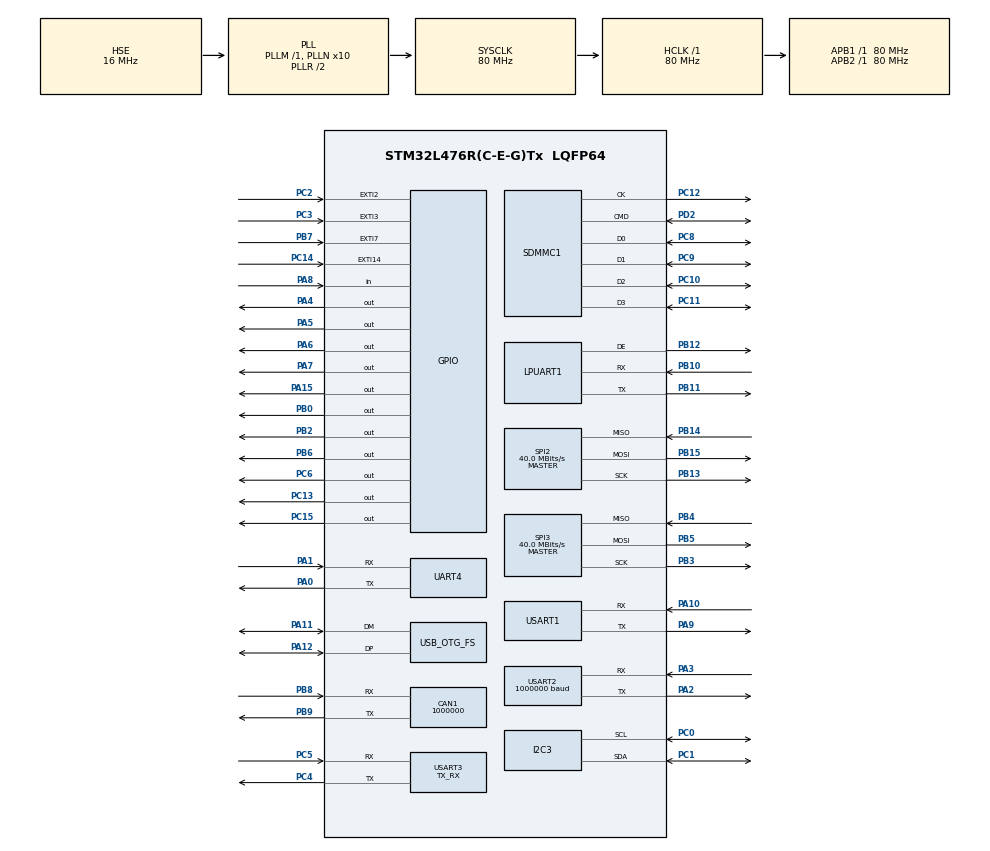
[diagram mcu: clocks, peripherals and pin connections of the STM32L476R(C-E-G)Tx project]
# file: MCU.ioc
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AL94.I-CUBE-USBD-COMPOSITE.1.0.3._STM32F1_DEVICE=false
AL94.I-CUBE-USBD-COMPOSITE.1.0.3._USBD_CDC_ACM_COUNT=1
AL94.I-CUBE-USBD-COMPOSITE.1.0.3._USBD_USE_CDC_ACM=true
AL94.I-CUBE-USBD-COMPOSITE.1.0.3._USBD_USE_MSC=true
CAN1.BS1=CAN_BS1_3TQ
CAN1.BS2=CAN_BS2_1TQ
CAN1.CalculateBaudRate=1000000
CAN1.CalculateTimeBit=1000
CAN1.CalculateTimeQuantum=200.0
Dma.Request0=SDMMC1
Dma.SDMMC1.0.Direction=DMA_PERIPH_TO_MEMORY
Dma.SDMMC1.0.Instance=DMA2_Channel4
Dma.SDMMC1.0.MemDataAlignment=DMA_MDATAALIGN_WORD
Dma.SDMMC1.0.MemInc=DMA_MINC_ENABLE
Dma.SDMMC1.0.Mode=DMA_NORMAL
Dma.SDMMC1.0.PeriphDataAlignment=DMA_PDATAALIGN_WORD
Dma.SDMMC1.0.PeriphInc=DMA_PINC_DISABLE
Dma.SDMMC1.0.Priority=DMA_PRIORITY_LOW
FATFS._FS_REENTRANT=1
FATFS._MAX_LFN=255
FATFS._MAX_SS=512
FATFS._USE_LFN=2
FATFS._USE_STRFUNC=1
FREERTOS.Queues01=usbRxQueue,16,uint16_t,0,Dynamic,NULL,NULL
FREERTOS.Tasks01=defaultTask,0,128,StartDefaultTask,Default,NULL,Dynamic,NULL,NULL
FREERTOS.configENABLE_FPU=1
FREERTOS.configTOTAL_HEAP_SIZE=16384
FREERTOS.configUSE_NEWLIB_REENTRANT=1
I2C3.Timing=0x10909CEC
LPUART1.OneBitSampling=UART_ONE_BIT_SAMPLE_DISABLE
Mcu.Family=STM32L4
Mcu.Name=STM32L476R(C-E-G)Tx
Mcu.Package=LQFP64
NVIC.DMA2_Channel4_IRQn=true\:5\:0\:false\:false\:true\:true\:false\:true\:true
NVIC.OTG_FS_IRQn=true\:7\:0\:true\:false\:true\:true\:true\:true\:true
NVIC.PriorityGroup=NVIC_PRIORITYGROUP_4
NVIC.SDMMC1_IRQn=true\:6\:0\:true\:false\:true\:true\:true\:true\:true
NVIC.TIM1_BRK_TIM15_IRQn=true\:15\:0\:false\:false\:true\:false\:false\:true\:true
NVIC.TimeBase=TIM1_BRK_TIM15_IRQn
NVIC.TimeBaseIP=TIM15
PA0.Mode=Asynchronous
PA0.Signal=UART4_TX
PA1.Mode=Asynchronous
PA1.Signal=UART4_RX
PA10.Mode=Asynchronous
PA10.Signal=USART1_RX
PA11.Mode=Device_Only
PA11.Signal=USB_OTG_FS_DM
PA12.Mode=Device_Only
PA12.Signal=USB_OTG_FS_DP
PA13\ (JTMS-SWDIO).Mode=Serial_Wire
PA13\ (JTMS-SWDIO).Signal=SYS_JTMS-SWDIO
PA14\ (JTCK-SWCLK).Mode=Serial_Wire
PA14\ (JTCK-SWCLK).Signal=SYS_JTCK-SWCLK
PA15\ (JTDI).Signal=GPIO_Output
PA2.Mode=Asynchronous
PA2.Signal=USART2_TX
PA3.Mode=Asynchronous
PA3.Signal=USART2_RX
PA4.Signal=GPIO_Output
PA5.Signal=GPIO_Output
PA6.Signal=GPIO_Output
PA7.Signal=GPIO_Output
PA8.Signal=GPIO_Input
PA9.Mode=Asynchronous
PA9.Signal=USART1_TX
PB0.Signal=GPIO_Output
PB10.Mode=Asynchronous
PB10.Signal=LPUART1_RX
PB11.Mode=Asynchronous
PB11.Signal=LPUART1_TX
PB12.Mode=Hardware Flow Control (RS485)
PB12.Signal=LPUART1_DE
PB13.Mode=Full_Duplex_Master
PB13.Signal=SPI2_SCK
PB14.Mode=Full_Duplex_Master
PB14.Signal=SPI2_MISO
PB15.Mode=Full_Duplex_Master
PB15.Signal=SPI2_MOSI
PB2.Signal=GPIO_Output
PB3\ (JTDO-TRACESWO).Mode=Full_Duplex_Master
PB3\ (JTDO-TRACESWO).Signal=SPI3_SCK
PB4\ (NJTRST).Mode=Full_Duplex_Master
PB4\ (NJTRST).Signal=SPI3_MISO
PB5.Mode=Full_Duplex_Master
PB5.Signal=SPI3_MOSI
PB6.Signal=GPIO_Output
PB7.Signal=GPXTI7
PB8.Mode=CAN_Activate
PB8.Signal=CAN1_RX
PB9.Mode=CAN_Activate
PB9.Signal=CAN1_TX
PC0.Mode=I2C
PC0.Signal=I2C3_SCL
PC1.Mode=I2C
PC1.Signal=I2C3_SDA
PC10.Mode=mmc_4_bits_Wide_bus
PC10.Signal=SDMMC1_D2
PC11.Mode=mmc_4_bits_Wide_bus
PC11.Signal=SDMMC1_D3
PC12.Mode=mmc_4_bits_Wide_bus
PC12.Signal=SDMMC1_CK
PC13.Signal=GPIO_Output
PC14-OSC32_IN\ (PC14).Signal=GPXTI14
PC15-OSC32_OUT\ (PC15).Signal=GPIO_Output
PC2.Signal=GPXTI2
PC3.Signal=GPXTI3
PC4.Mode=Asynchronous
PC4.Signal=USART3_TX
PC5.Mode=Asynchronous
PC5.Signal=USART3_RX
PC6.Signal=GPIO_Output
PC8.Mode=mmc_4_bits_Wide_bus
PC8.Signal=SDMMC1_D0
PC9.Mode=mmc_4_bits_Wide_bus
PC9.Signal=SDMMC1_D1
PD2.Mode=mmc_4_bits_Wide_bus
PD2.Signal=SDMMC1_CMD
PH0-OSC_IN\ (PH0).Mode=HSE-External-Oscillator
PH0-OSC_IN\ (PH0).Signal=RCC_OSC_IN
PH1-OSC_OUT\ (PH1).Mode=HSE-External-Oscillator
PH1-OSC_OUT\ (PH1).Signal=RCC_OSC_OUT
ProjectManager.HeapSize=0x1000
ProjectManager.StackSize=0x3000
ProjectManager.TargetToolchain=STM32CubeIDE
RCC.ADCFreq_Value=96000000
RCC.AHBFreq_Value=80000000
RCC.APB1Freq_Value=80000000
RCC.APB1TimFreq_Value=80000000
RCC.APB2Freq_Value=80000000
RCC.APB2TimFreq_Value=80000000
RCC.CortexFreq_Value=80000000
RCC.HCLKFreq_Value=80000000
RCC.HSE_VALUE=16000000
RCC.HSI_VALUE=16000000
RCC.LSE_VALUE=32768
RCC.MSIClockRange=RCC_MSIRANGE_9
RCC.MSI_VALUE=24000000
RCC.PLLN=10
RCC.PLLQ=RCC_PLLQ_DIV4
RCC.PLLSAI1N=12
RCC.PLLSAI1Q=RCC_PLLQ_DIV4
RCC.PLLSourceVirtual=RCC_PLLSOURCE_HSE
RCC.SYSCLKFreq_VALUE=80000000
RCC.SYSCLKSource=RCC_SYSCLKSOURCE_PLLCLK
RCC.USBFreq_Value=48000000
RCC.VCOOutputFreq_Value=160000000
SDMMC1.ClockDiv=0
SDMMC1.HardwareFlowControl=SDMMC_HARDWARE_FLOW_CONTROL_ENABLE
SPI2.BaudRatePrescaler=SPI_BAUDRATEPRESCALER_2
SPI2.CalculateBaudRate=40.0 MBits/s
SPI2.Direction=SPI_DIRECTION_2LINES
SPI2.Mode=SPI_MODE_MASTER
SPI2.VirtualType=VM_MASTER
SPI3.BaudRatePrescaler=SPI_BAUDRATEPRESCALER_2
SPI3.CalculateBaudRate=40.0 MBits/s
SPI3.Direction=SPI_DIRECTION_2LINES
SPI3.Mode=SPI_MODE_MASTER
SPI3.VirtualType=VM_MASTER
UART4.OverSampling=UART_OVERSAMPLING_8
UART4.Parity=PARITY_EVEN
UART4.StopBits=UART_STOPBITS_2
USART1.OneBitSampling=UART_ONE_BIT_SAMPLE_DISABLE
USART1.OverSampling=UART_OVERSAMPLING_8
USART1.SwapParam=ADVFEATURE_SWAP_DISABLE
USART1.VirtualMode-Asynchronous=VM_ASYNC
USART2.BaudRate=1000000
USART2.VirtualMode-Asynchronous=VM_ASYNC
USART3.AutoBaudRateEnableParam=UART_ADVFEATURE_AUTOBAUDRATE_DISABLE
USART3.Mode=MODE_TX_RX
USART3.OneBitSampling=UART_ONE_BIT_SAMPLE_ENABLE
USART3.OverSampling=UART_OVERSAMPLING_8
USART3.VirtualMode-Asynchronous=VM_ASYNC
USB_OTG_FS.VirtualMode=Device_Only
VP_CRC_VS_CRC.Mode=CRC_Activate
VP_FATFS_VS_Generic.Mode=User_defined
VP_FREERTOS_VS_CMSIS_V1.Mode=CMSIS_V1
VP_SYS_VS_tim15.Mode=TIM15
VP_SYS_V_PVD_IN.Mode=Mode_PVD_Int
board=custom

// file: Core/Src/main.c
/* USER CODE BEGIN Header */
/**
 ******************************************************************************
 * @file           : main.c
 * @brief          : Main program body
 ******************************************************************************
 * @attention
 *
 * Copyright (c) 2024 STMicroelectronics.
 * All rights reserved.
 *
 * This software is licensed under terms that can be found in the LICENSE file
 * in the root directory of this software component.
 * If no LICENSE file comes with this software, it is provided AS-IS.
 *
 ******************************************************************************
 */
/* USER CODE END Header */
#include "main.h"
#include "cmsis_os.h"
#include "fatfs.h"

/* USER CODE BEGIN Includes */
// #include "mmc_ops.h"
#include "logging.h"
#include "usb_device.h"
#include "ringbuffer.h"
#include "entrypoint.h"
/* USER CODE END Includes */

CAN_HandleTypeDef hcan1;

CRC_HandleTypeDef hcrc;

I2C_HandleTypeDef hi2c3;

UART_HandleTypeDef hlpuart1;
UART_HandleTypeDef huart4;
UART_HandleTypeDef huart1;
UART_HandleTypeDef huart2;
UART_HandleTypeDef huart3;

MMC_HandleTypeDef hmmc1;
DMA_HandleTypeDef hdma_sdmmc1;

SPI_HandleTypeDef hspi2;
SPI_HandleTypeDef hspi3;

PCD_HandleTypeDef hpcd_USB_OTG_FS;

osThreadId defaultTaskHandle;
osMessageQId usbRxQueueHandle;
/* USER CODE BEGIN PV */
osThreadId entrypointTaskHandle;
/* USER CODE END PV */

void SystemClock_Config(void);
void PeriphCommonClock_Config(void);
static void MX_GPIO_Init(void);
static void MX_DMA_Init(void);
static void MX_CAN1_Init(void);
static void MX_I2C3_Init(void);
static void MX_LPUART1_UART_Init(void);
static void MX_UART4_Init(void);
static void MX_USART1_UART_Init(void);
static void MX_USART2_UART_Init(void);
static void MX_USART3_UART_Init(void);
static void MX_SDMMC1_MMC_Init(void);
static void MX_SPI3_Init(void);
static void MX_SPI2_Init(void);
static void MX_CRC_Init(void);
static void MX_USB_OTG_FS_PCD_Init(void);
void StartDefaultTask(void const * argument);

/* USER CODE BEGIN PFP */
void StartMMCWriteTask(void const *argument);
/* USER CODE END PFP */

int main(void)
{

  /* MCU Configuration--------------------------------------------------------*/

  /* Reset of all peripherals, Initializes the Flash interface and the Systick. */
  HAL_Init();

  /* Configure the system clock */
  SystemClock_Config();

/* Configure the peripherals common clocks */
  PeriphCommonClock_Config();

  /* USER CODE BEGIN SysInit */
  // ring_buffer_init(&usb_rx_ringbuffer, usb_rx_buf, sizeof(usb_rx_buf));
  /* USER CODE END SysInit */

  /* Initialize all configured peripherals */
  MX_GPIO_Init();
  MX_DMA_Init();
  MX_CAN1_Init();
  MX_I2C3_Init();
  MX_LPUART1_UART_Init();
  MX_UART4_Init();
  MX_USART1_UART_Init();
  MX_USART2_UART_Init();
  MX_USART3_UART_Init();
  MX_SDMMC1_MMC_Init();
  MX_SPI3_Init();
  MX_SPI2_Init();
  MX_CRC_Init();
  MX_FATFS_Init();
  MX_USB_OTG_FS_PCD_Init();
  /* USER CODE BEGIN 2 */
  HAL_PWREx_EnableVddUSB();
  MX_USB_DEVICE_Init();

  /* USER CODE END 2 */

  /* Create the queue(s) */
  /* definition and creation of usbRxQueue */
  osMessageQDef(usbRxQueue, 16, uint16_t);
  usbRxQueueHandle = osMessageCreate(osMessageQ(usbRxQueue), NULL);

  /* USER CODE BEGIN RTOS_QUEUES */
  /* add queues, ... */

#if 0
  /* USER CODE END RTOS_QUEUES */

  /* Create the thread(s) */
  /* definition and creation of defaultTask */
  osThreadDef(defaultTask, StartDefaultTask, osPriorityNormal, 0, 128);
  defaultTaskHandle = osThreadCreate(osThread(defaultTask), NULL);

  /* USER CODE BEGIN RTOS_THREADS */
#endif
  osThreadDef(entrypointTask, StartEntrypointTask, osPriorityNormal, 0, 128);
  entrypointTaskHandle = osThreadCreate(osThread(entrypointTask), NULL);
  /* definition and creation of mmcWriteTask */
  /* USER CODE END RTOS_THREADS */

  /* Start scheduler */
  osKernelStart();

  /* We should never get here as control is now taken by the scheduler */

  /* Infinite loop */
  while (1)
  {

  }
}

void SystemClock_Config(void)
{
  RCC_OscInitTypeDef RCC_OscInitStruct = {0};
  RCC_ClkInitTypeDef RCC_ClkInitStruct = {0};

  /** Configure the main internal regulator output voltage
  */
  if (HAL_PWREx_ControlVoltageScaling(PWR_REGULATOR_VOLTAGE_SCALE1) != HAL_OK)
  {
    Error_Handler();
  }

  /** Initializes the RCC Oscillators according to the specified parameters
  * in the RCC_OscInitTypeDef structure.
  */
  RCC_OscInitStruct.OscillatorType = RCC_OSCILLATORTYPE_HSE;
  RCC_OscInitStruct.HSEState = RCC_HSE_ON;
  RCC_OscInitStruct.PLL.PLLState = RCC_PLL_ON;
  RCC_OscInitStruct.PLL.PLLSource = RCC_PLLSOURCE_HSE;
  RCC_OscInitStruct.PLL.PLLM = 1;
  RCC_OscInitStruct.PLL.PLLN = 10;
  RCC_OscInitStruct.PLL.PLLP = RCC_PLLP_DIV7;
  RCC_OscInitStruct.PLL.PLLQ = RCC_PLLQ_DIV4;
  RCC_OscInitStruct.PLL.PLLR = RCC_PLLR_DIV2;
  if (HAL_RCC_OscConfig(&RCC_OscInitStruct) != HAL_OK)
  {
    Error_Handler();
  }

  /** Initializes the CPU, AHB and APB buses clocks
  */
  RCC_ClkInitStruct.ClockType = RCC_CLOCKTYPE_HCLK|RCC_CLOCKTYPE_SYSCLK
                              |RCC_CLOCKTYPE_PCLK1|RCC_CLOCKTYPE_PCLK2;
  RCC_ClkInitStruct.SYSCLKSource = RCC_SYSCLKSOURCE_PLLCLK;
  RCC_ClkInitStruct.AHBCLKDivider = RCC_SYSCLK_DIV1;
  RCC_ClkInitStruct.APB1CLKDivider = RCC_HCLK_DIV1;
  RCC_ClkInitStruct.APB2CLKDivider = RCC_HCLK_DIV1;

  if (HAL_RCC_ClockConfig(&RCC_ClkInitStruct, FLASH_LATENCY_4) != HAL_OK)
  {
    Error_Handler();
  }
}

void PeriphCommonClock_Config(void)
{
  RCC_PeriphCLKInitTypeDef PeriphClkInit = {0};

  /** Initializes the peripherals clock
  */
  PeriphClkInit.PeriphClockSelection = RCC_PERIPHCLK_USB|RCC_PERIPHCLK_SDMMC1;
  PeriphClkInit.UsbClockSelection = RCC_USBCLKSOURCE_PLLSAI1;
  PeriphClkInit.Sdmmc1ClockSelection = RCC_SDMMC1CLKSOURCE_PLLSAI1;
  PeriphClkInit.PLLSAI1.PLLSAI1Source = RCC_PLLSOURCE_HSE;
  PeriphClkInit.PLLSAI1.PLLSAI1M = 1;
  PeriphClkInit.PLLSAI1.PLLSAI1N = 12;
  PeriphClkInit.PLLSAI1.PLLSAI1P = RCC_PLLP_DIV7;
  PeriphClkInit.PLLSAI1.PLLSAI1Q = RCC_PLLQ_DIV4;
  PeriphClkInit.PLLSAI1.PLLSAI1R = RCC_PLLR_DIV2;
  PeriphClkInit.PLLSAI1.PLLSAI1ClockOut = RCC_PLLSAI1_48M2CLK;
  if (HAL_RCCEx_PeriphCLKConfig(&PeriphClkInit) != HAL_OK)
  {
    Error_Handler();
  }
}

static void MX_CAN1_Init(void)
{

  hcan1.Instance = CAN1;
  hcan1.Init.Prescaler = 16;
  hcan1.Init.Mode = CAN_MODE_NORMAL;
  hcan1.Init.SyncJumpWidth = CAN_SJW_1TQ;
  hcan1.Init.TimeSeg1 = CAN_BS1_3TQ;
  hcan1.Init.TimeSeg2 = CAN_BS2_1TQ;
  hcan1.Init.TimeTriggeredMode = DISABLE;
  hcan1.Init.AutoBusOff = DISABLE;
  hcan1.Init.AutoWakeUp = DISABLE;
  hcan1.Init.AutoRetransmission = DISABLE;
  hcan1.Init.ReceiveFifoLocked = DISABLE;
  hcan1.Init.TransmitFifoPriority = DISABLE;
  if (HAL_CAN_Init(&hcan1) != HAL_OK)
  {
    Error_Handler();
  }

}

static void MX_CRC_Init(void)
{

  hcrc.Instance = CRC;
  hcrc.Init.DefaultPolynomialUse = DEFAULT_POLYNOMIAL_ENABLE;
  hcrc.Init.DefaultInitValueUse = DEFAULT_INIT_VALUE_ENABLE;
  hcrc.Init.InputDataInversionMode = CRC_INPUTDATA_INVERSION_NONE;
  hcrc.Init.OutputDataInversionMode = CRC_OUTPUTDATA_INVERSION_DISABLE;
  hcrc.InputDataFormat = CRC_INPUTDATA_FORMAT_BYTES;
  if (HAL_CRC_Init(&hcrc) != HAL_OK)
  {
    Error_Handler();
  }

}

static void MX_I2C3_Init(void)
{

  hi2c3.Instance = I2C3;
  hi2c3.Init.Timing = 0x10909CEC;
  hi2c3.Init.OwnAddress1 = 0;
  hi2c3.Init.AddressingMode = I2C_ADDRESSINGMODE_7BIT;
  hi2c3.Init.DualAddressMode = I2C_DUALADDRESS_DISABLE;
  hi2c3.Init.OwnAddress2 = 0;
  hi2c3.Init.OwnAddress2Masks = I2C_OA2_NOMASK;
  hi2c3.Init.GeneralCallMode = I2C_GENERALCALL_DISABLE;
  hi2c3.Init.NoStretchMode = I2C_NOSTRETCH_DISABLE;
  if (HAL_I2C_Init(&hi2c3) != HAL_OK)
  {
    Error_Handler();
  }

  /** Configure Analogue filter
  */
  if (HAL_I2CEx_ConfigAnalogFilter(&hi2c3, I2C_ANALOGFILTER_ENABLE) != HAL_OK)
  {
    Error_Handler();
  }

  /** Configure Digital filter
  */
  if (HAL_I2CEx_ConfigDigitalFilter(&hi2c3, 0) != HAL_OK)
  {
    Error_Handler();
  }

}

static void MX_LPUART1_UART_Init(void)
{

  hlpuart1.Instance = LPUART1;
  hlpuart1.Init.BaudRate = 209700;
  hlpuart1.Init.WordLength = UART_WORDLENGTH_7B;
  hlpuart1.Init.StopBits = UART_STOPBITS_1;
  hlpuart1.Init.Parity = UART_PARITY_NONE;
  hlpuart1.Init.Mode = UART_MODE_TX_RX;
  hlpuart1.Init.HwFlowCtl = UART_HWCONTROL_NONE;
  hlpuart1.Init.OneBitSampling = UART_ONE_BIT_SAMPLE_DISABLE;
  hlpuart1.AdvancedInit.AdvFeatureInit = UART_ADVFEATURE_NO_INIT;
  if (HAL_RS485Ex_Init(&hlpuart1, UART_DE_POLARITY_HIGH, 0, 0) != HAL_OK)
  {
    Error_Handler();
  }

}

static void MX_UART4_Init(void)
{

  huart4.Instance = UART4;
  huart4.Init.BaudRate = 115200;
  huart4.Init.WordLength = UART_WORDLENGTH_8B;
  huart4.Init.StopBits = UART_STOPBITS_2;
  huart4.Init.Parity = UART_PARITY_EVEN;
  huart4.Init.Mode = UART_MODE_TX_RX;
  huart4.Init.HwFlowCtl = UART_HWCONTROL_NONE;
  huart4.Init.OverSampling = UART_OVERSAMPLING_8;
  huart4.Init.OneBitSampling = UART_ONE_BIT_SAMPLE_DISABLE;
  huart4.AdvancedInit.AdvFeatureInit = UART_ADVFEATURE_NO_INIT;
  if (HAL_UART_Init(&huart4) != HAL_OK)
  {
    Error_Handler();
  }

}

static void MX_USART1_UART_Init(void)
{

  huart1.Instance = USART1;
  huart1.Init.BaudRate = 115200;
  huart1.Init.WordLength = UART_WORDLENGTH_8B;
  huart1.Init.StopBits = UART_STOPBITS_1;
  huart1.Init.Parity = UART_PARITY_NONE;
  huart1.Init.Mode = UART_MODE_TX_RX;
  huart1.Init.HwFlowCtl = UART_HWCONTROL_NONE;
  huart1.Init.OverSampling = UART_OVERSAMPLING_8;
  huart1.Init.OneBitSampling = UART_ONE_BIT_SAMPLE_DISABLE;
  huart1.AdvancedInit.AdvFeatureInit = UART_ADVFEATURE_NO_INIT;
  if (HAL_UART_Init(&huart1) != HAL_OK)
  {
    Error_Handler();
  }

}

static void MX_USART2_UART_Init(void)
{

  huart2.Instance = USART2;
  huart2.Init.BaudRate = 1000000;
  huart2.Init.WordLength = UART_WORDLENGTH_8B;
  huart2.Init.StopBits = UART_STOPBITS_1;
  huart2.Init.Parity = UART_PARITY_NONE;
  huart2.Init.Mode = UART_MODE_TX_RX;
  huart2.Init.HwFlowCtl = UART_HWCONTROL_NONE;
  huart2.Init.OverSampling = UART_OVERSAMPLING_16;
  huart2.Init.OneBitSampling = UART_ONE_BIT_SAMPLE_DISABLE;
  huart2.AdvancedInit.AdvFeatureInit = UART_ADVFEATURE_NO_INIT;
  if (HAL_UART_Init(&huart2) != HAL_OK)
  {
    Error_Handler();
  }

}

static void MX_USART3_UART_Init(void)
{

  huart3.Instance = USART3;
  huart3.Init.BaudRate = 115200;
  huart3.Init.WordLength = UART_WORDLENGTH_8B;
  huart3.Init.StopBits = UART_STOPBITS_1;
  huart3.Init.Parity = UART_PARITY_NONE;
  huart3.Init.Mode = UART_MODE_TX_RX;
  huart3.Init.HwFlowCtl = UART_HWCONTROL_NONE;
  huart3.Init.OverSampling = UART_OVERSAMPLING_8;
  huart3.Init.OneBitSampling = UART_ONE_BIT_SAMPLE_ENABLE;
  huart3.AdvancedInit.AdvFeatureInit = UART_ADVFEATURE_NO_INIT;
  if (HAL_UART_Init(&huart3) != HAL_OK)
  {
    Error_Handler();
  }

}

static void MX_SDMMC1_MMC_Init(void)
{

  hmmc1.Instance = SDMMC1;
  hmmc1.Init.ClockEdge = SDMMC_CLOCK_EDGE_RISING;
  hmmc1.Init.ClockBypass = SDMMC_CLOCK_BYPASS_DISABLE;
  hmmc1.Init.ClockPowerSave = SDMMC_CLOCK_POWER_SAVE_DISABLE;
  hmmc1.Init.BusWide = SDMMC_BUS_WIDE_4B;
  hmmc1.Init.HardwareFlowControl = SDMMC_HARDWARE_FLOW_CONTROL_ENABLE;
  hmmc1.Init.ClockDiv = 0;
  if (HAL_MMC_Init(&hmmc1) != HAL_OK)
  {
    Error_Handler();
  }
  if (HAL_MMC_ConfigWideBusOperation(&hmmc1, SDMMC_BUS_WIDE_4B) != HAL_OK)
  {
    Error_Handler();
  }

}

static void MX_SPI2_Init(void)
{

  /* SPI2 parameter configuration*/
  hspi2.Instance = SPI2;
  hspi2.Init.Mode = SPI_MODE_MASTER;
  hspi2.Init.Direction = SPI_DIRECTION_2LINES;
  hspi2.Init.DataSize = SPI_DATASIZE_4BIT;
  hspi2.Init.CLKPolarity = SPI_POLARITY_LOW;
  hspi2.Init.CLKPhase = SPI_PHASE_1EDGE;
  hspi2.Init.NSS = SPI_NSS_SOFT;
  hspi2.Init.BaudRatePrescaler = SPI_BAUDRATEPRESCALER_2;
  hspi2.Init.FirstBit = SPI_FIRSTBIT_MSB;
  hspi2.Init.TIMode = SPI_TIMODE_DISABLE;
  hspi2.Init.CRCCalculation = SPI_CRCCALCULATION_DISABLE;
  hspi2.Init.CRCPolynomial = 7;
  hspi2.Init.CRCLength = SPI_CRC_LENGTH_DATASIZE;
  hspi2.Init.NSSPMode = SPI_NSS_PULSE_ENABLE;
  if (HAL_SPI_Init(&hspi2) != HAL_OK)
  {
    Error_Handler();
  }

}

static void MX_SPI3_Init(void)
{

  /* SPI3 parameter configuration*/
  hspi3.Instance = SPI3;
  hspi3.Init.Mode = SPI_MODE_MASTER;
  hspi3.Init.Direction = SPI_DIRECTION_2LINES;
  hspi3.Init.DataSize = SPI_DATASIZE_4BIT;
  hspi3.Init.CLKPolarity = SPI_POLARITY_LOW;
  hspi3.Init.CLKPhase = SPI_PHASE_1EDGE;
  hspi3.Init.NSS = SPI_NSS_SOFT;
  hspi3.Init.BaudRatePrescaler = SPI_BAUDRATEPRESCALER_2;
  hspi3.Init.FirstBit = SPI_FIRSTBIT_MSB;
  hspi3.Init.TIMode = SPI_TIMODE_DISABLE;
  hspi3.Init.CRCCalculation = SPI_CRCCALCULATION_DISABLE;
  hspi3.Init.CRCPolynomial = 7;
  hspi3.Init.CRCLength = SPI_CRC_LENGTH_DATASIZE;
  hspi3.Init.NSSPMode = SPI_NSS_PULSE_ENABLE;
  if (HAL_SPI_Init(&hspi3) != HAL_OK)
  {
    Error_Handler();
  }

}

static void MX_USB_OTG_FS_PCD_Init(void)
{

  hpcd_USB_OTG_FS.Instance = USB_OTG_FS;
  hpcd_USB_OTG_FS.Init.dev_endpoints = 6;
  hpcd_USB_OTG_FS.Init.speed = PCD_SPEED_FULL;
  hpcd_USB_OTG_FS.Init.phy_itface = PCD_PHY_EMBEDDED;
  hpcd_USB_OTG_FS.Init.Sof_enable = DISABLE;
  hpcd_USB_OTG_FS.Init.low_power_enable = DISABLE;
  hpcd_USB_OTG_FS.Init.lpm_enable = DISABLE;
  hpcd_USB_OTG_FS.Init.battery_charging_enable = DISABLE;
  hpcd_USB_OTG_FS.Init.use_dedicated_ep1 = DISABLE;
  hpcd_USB_OTG_FS.Init.vbus_sensing_enable = DISABLE;
  if (HAL_PCD_Init(&hpcd_USB_OTG_FS) != HAL_OK)
  {
    Error_Handler();
  }

}

static void MX_DMA_Init(void)
{

  /* DMA controller clock enable */
  __HAL_RCC_DMA2_CLK_ENABLE();

  /* DMA interrupt init */
  /* DMA2_Channel4_IRQn interrupt configuration */
  HAL_NVIC_SetPriority(DMA2_Channel4_IRQn, 5, 0);
  HAL_NVIC_EnableIRQ(DMA2_Channel4_IRQn);

}

static void MX_GPIO_Init(void)
{
  GPIO_InitTypeDef GPIO_InitStruct = {0};

  /* GPIO Ports Clock Enable */
  __HAL_RCC_GPIOC_CLK_ENABLE();
  __HAL_RCC_GPIOH_CLK_ENABLE();
  __HAL_RCC_GPIOA_CLK_ENABLE();
  __HAL_RCC_GPIOB_CLK_ENABLE();
  __HAL_RCC_GPIOD_CLK_ENABLE();

  /*Configure GPIO pin Output Level */
  HAL_GPIO_WritePin(GPIOC, GPIO_PIN_13|GPIO_PIN_15|GPIO_PIN_6, GPIO_PIN_RESET);

  /*Configure GPIO pin Output Level */
  HAL_GPIO_WritePin(GPIOA, GPIO_PIN_4|GPIO_PIN_5|GPIO_PIN_6|GPIO_PIN_7
                          |GPIO_PIN_15, GPIO_PIN_RESET);

  /*Configure GPIO pin Output Level */
  HAL_GPIO_WritePin(GPIOB, GPIO_PIN_0|GPIO_PIN_2|GPIO_PIN_6, GPIO_PIN_RESET);

  /*Configure GPIO pins : PC13 PC15 PC6 */
  GPIO_InitStruct.Pin = GPIO_PIN_13|GPIO_PIN_15|GPIO_PIN_6;
  GPIO_InitStruct.Mode = GPIO_MODE_OUTPUT_PP;
  GPIO_InitStruct.Pull = GPIO_NOPULL;
  GPIO_InitStruct.Speed = GPIO_SPEED_FREQ_LOW;
  HAL_GPIO_Init(GPIOC, &GPIO_InitStruct);

  /*Configure GPIO pins : PC14 PC2 PC3 */
  GPIO_InitStruct.Pin = GPIO_PIN_14|GPIO_PIN_2|GPIO_PIN_3;
  GPIO_InitStruct.Mode = GPIO_MODE_IT_RISING;
  GPIO_InitStruct.Pull = GPIO_NOPULL;
  HAL_GPIO_Init(GPIOC, &GPIO_InitStruct);

  /*Configure GPIO pins : PA4 PA5 PA6 PA7
                           PA15 */
  GPIO_InitStruct.Pin = GPIO_PIN_4|GPIO_PIN_5|GPIO_PIN_6|GPIO_PIN_7
                          |GPIO_PIN_15;
  GPIO_InitStruct.Mode = GPIO_MODE_OUTPUT_PP;
  GPIO_InitStruct.Pull = GPIO_NOPULL;
  GPIO_InitStruct.Speed = GPIO_SPEED_FREQ_LOW;
  HAL_GPIO_Init(GPIOA, &GPIO_InitStruct);

  /*Configure GPIO pins : PB0 PB2 PB6 */
  GPIO_InitStruct.Pin = GPIO_PIN_0|GPIO_PIN_2|GPIO_PIN_6;
  GPIO_InitStruct.Mode = GPIO_MODE_OUTPUT_PP;
  GPIO_InitStruct.Pull = GPIO_NOPULL;
  GPIO_InitStruct.Speed = GPIO_SPEED_FREQ_LOW;
  HAL_GPIO_Init(GPIOB, &GPIO_InitStruct);

  /*Configure GPIO pin : PA8 */
  GPIO_InitStruct.Pin = GPIO_PIN_8;
  GPIO_InitStruct.Mode = GPIO_MODE_INPUT;
  GPIO_InitStruct.Pull = GPIO_NOPULL;
  HAL_GPIO_Init(GPIOA, &GPIO_InitStruct);

  /*Configure GPIO pin : PB7 */
  GPIO_InitStruct.Pin = GPIO_PIN_7;
  GPIO_InitStruct.Mode = GPIO_MODE_IT_RISING;
  GPIO_InitStruct.Pull = GPIO_NOPULL;
  HAL_GPIO_Init(GPIOB, &GPIO_InitStruct);

}

void StartDefaultTask(void const * argument)
{
  for (;;)
  {
    osDelay(1);
  }
}

void HAL_TIM_PeriodElapsedCallback(TIM_HandleTypeDef *htim)
{
  if (htim->Instance == TIM15) {
    HAL_IncTick();
  }
}

void Error_Handler(void)
{
  /* USER CODE BEGIN Error_Handler_Debug */
  /* User can add his own implementation to report the HAL error return state */
  __disable_irq();
  __BKPT();
  while (1)
  {
  }
  /* USER CODE END Error_Handler_Debug */
}
